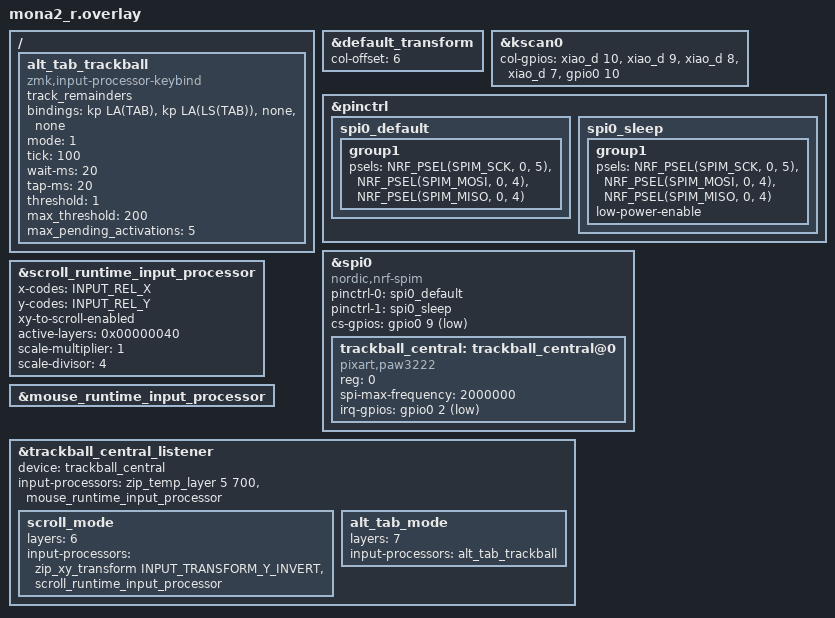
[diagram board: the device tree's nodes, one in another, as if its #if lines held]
#include "mona2.dtsi"

/*
 * mona2.dtsi 内で RC(row,col) のマトリクス展開が終わった後に include。
 * runtime-input-processor.dtsi が modifiers.h 経由で RC(keycode) を
 * 再定義するため、この順序を維持する。
 */
#include <input/processors/runtime-input-processor.dtsi>
#include <input/processors.dtsi>
#include <input/processors/zmk-input-processor-keybind.dtsi>

#include <dt-bindings/zmk/input_transform.h>
#include <dt-bindings/zmk/keys.h>
#include <zephyr/dt-bindings/input/input-event-codes.h>


&default_transform {
    col-offset = <6>;
};


&kscan0 {
    col-gpios
        = <&xiao_d 10 GPIO_ACTIVE_HIGH>
        , <&xiao_d 9 GPIO_ACTIVE_HIGH>
        , <&xiao_d 8 GPIO_ACTIVE_HIGH>
        , <&xiao_d 7 GPIO_ACTIVE_HIGH>
        , <&gpio0 10 GPIO_ACTIVE_HIGH>
        ;
};


/* ============================================================
 * Trackball hardware
 * ============================================================ */

&pinctrl {
    spi0_default: spi0_default {
        group1 {
            psels = <NRF_PSEL(SPIM_SCK, 0, 5)>,
                    <NRF_PSEL(SPIM_MOSI, 0, 4)>,
                    <NRF_PSEL(SPIM_MISO, 0, 4)>;
        };
    };

    spi0_sleep: spi0_sleep {
        group1 {
            psels = <NRF_PSEL(SPIM_SCK, 0, 5)>,
                    <NRF_PSEL(SPIM_MOSI, 0, 4)>,
                    <NRF_PSEL(SPIM_MISO, 0, 4)>;
            low-power-enable;
        };
    };
};


&spi0 {
    status = "okay";
    compatible = "nordic,nrf-spim";

    pinctrl-0 = <&spi0_default>;
    pinctrl-1 = <&spi0_sleep>;
    pinctrl-names = "default", "sleep";

    cs-gpios = <&gpio0 9 GPIO_ACTIVE_LOW>;

    trackball_central: trackball_central@0 {
        status = "okay";

#ifdef CONFIG_TRACKBALL_PAW3222
        compatible = "pixart,paw3222";
        reg = <0>;
        spi-max-frequency = <2000000>;
        irq-gpios = <&gpio0 2 (GPIO_ACTIVE_LOW | GPIO_PULL_UP)>;

#else
        compatible = "pixart,pmw3610";
        reg = <0>;
        spi-max-frequency = <2000000>;
        irq-gpios = <&gpio0 2 (GPIO_ACTIVE_LOW | GPIO_PULL_UP)>;

        cpi = <600>;
        invert-x;

        evt-type = <INPUT_EV_REL>;
        x-input-code = <INPUT_REL_X>;
        y-input-code = <INPUT_REL_Y>;
#endif
    };
};


/* ============================================================
 * Layer 6 : SCROLL
 *
 * Trackball XY movement → horizontal / vertical scroll
 *
 * layer 6 only:
 *   bit 6 = 0x40
 *
 * 以前は layer 6 + 7 = 0xC0 だったが、
 * layer 7 は今後 Alt+Tab 用なので除外。
 * ============================================================ */

&scroll_runtime_input_processor {
    x-codes = <INPUT_REL_X>;
    y-codes = <INPUT_REL_Y>;

    xy-to-scroll-enabled;

    active-layers = <0x00000040>;

    scale-multiplier = <1>;
    scale-divisor = <4>;
};


/* ============================================================
 * Normal mouse processor
 * ============================================================ */

&mouse_runtime_input_processor {
};


/* ============================================================
 * Layer 7 : Trackball → Alt+Tab
 *
 * zmk-input-processor-keybind の bindings の順番:
 *
 *   1. RIGHT
 *   2. LEFT
 *   3. DOWN
 *   4. UP
 *
 * 今回:
 *
 *   RIGHT → Alt + Tab
 *   LEFT  → Alt + Shift + Tab
 *   DOWN  → none
 *   UP    → none
 *
 * roBaに近い操作感になるよう:
 *   tick    = 100
 *   wait-ms = 20
 *   tap-ms  = 20
 * ============================================================ */

/ {
    alt_tab_trackball: alt_tab_trackball {
        compatible = "zmk,input-processor-keybind";
        #input-processor-cells = <0>;

        track_remainders;

        bindings =
            <&kp LA(TAB)>,
            <&kp LA(LS(TAB))>,
            <&none>,
            <&none>;

        mode = <1>;

        tick = <100>;
        wait-ms = <20>;
        tap-ms = <20>;

        threshold = <1>;
        max_threshold = <200>;
        max_pending_activations = <5>;
    };
};


/* ============================================================
 * Trackball input listener
 *
 * Layer mapping:
 *
 *   5 = MOUSE
 *   6 = SCROLL
 *   7 = ALT-TAB
 *
 * 優先順位:
 *
 *   Layer 6 / Layer 7 が有効なら、その専用処理を行う。
 *   それ以外では通常マウス移動 +
 *   Layer 5 Auto Mouse。
 * ============================================================ */

&trackball_central_listener {
    status = "okay";
    device = <&trackball_central>;


    /*
     * --------------------------------------------------------
     * Layer 6 : SCROLL
     *
     * Yを反転してからscroll processorへ渡す。
     *
     * これにより現在の
     *   Ball UP   → scrollbar DOWN
     *   Ball DOWN → scrollbar UP
     *
     * を逆転させる。
     * --------------------------------------------------------
     */

    scroll_mode {
        layers = <6>;

        input-processors =
            <&zip_xy_transform INPUT_TRANSFORM_Y_INVERT>,
            <&scroll_runtime_input_processor>;
    };


    /*
     * --------------------------------------------------------
     * Layer 7 : ALT-TAB
     *
     * RIGHT → Alt+Tab
     * LEFT  → Alt+Shift+Tab
     *
     * このoverride中はAuto Mouseを発動させない。
     * --------------------------------------------------------
     */

    alt_tab_mode {
        layers = <7>;

        input-processors =
            <&alt_tab_trackball>;
    };


    /*
     * --------------------------------------------------------
     * NORMAL / AUTO MOUSE
     *
     * Trackball movement
     *      ↓
     * Layer 5 ON
     *
     * 最後のtrackball inputから700ms経過
     *      ↓
     * Layer 5 OFF
     *
     * roBa:
     * CONFIG_PMW3610_AUTOMOUSE_TIMEOUT_MS=700
     * と同じtimeout。
     * --------------------------------------------------------
     */

    input-processors =
        <&zip_temp_layer 5 700>,
        <&mouse_runtime_input_processor>;
};
